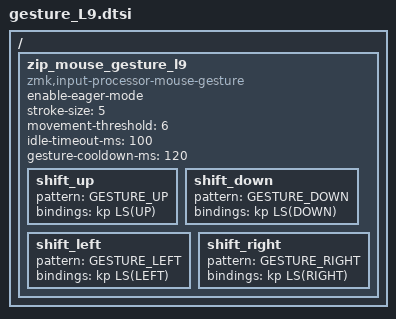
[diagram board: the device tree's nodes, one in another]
/ {
  zip_mouse_gesture_l9: zip_mouse_gesture_l9 {
    compatible = "zmk,input-processor-mouse-gesture";
    #input-processor-cells = <0>;
    enable-eager-mode;
    stroke-size = <5>;
    movement-threshold = <6>;
    idle-timeout-ms = <100>;
    gesture-cooldown-ms = <120>;

    shift_up    { pattern = <GESTURE_UP>;    bindings = <&kp LS(UP)>;    };
    shift_down  { pattern = <GESTURE_DOWN>;  bindings = <&kp LS(DOWN)>;  };
    shift_left  { pattern = <GESTURE_LEFT>;  bindings = <&kp LS(LEFT)>;  };
    shift_right { pattern = <GESTURE_RIGHT>; bindings = <&kp LS(RIGHT)>; };
  };
};
